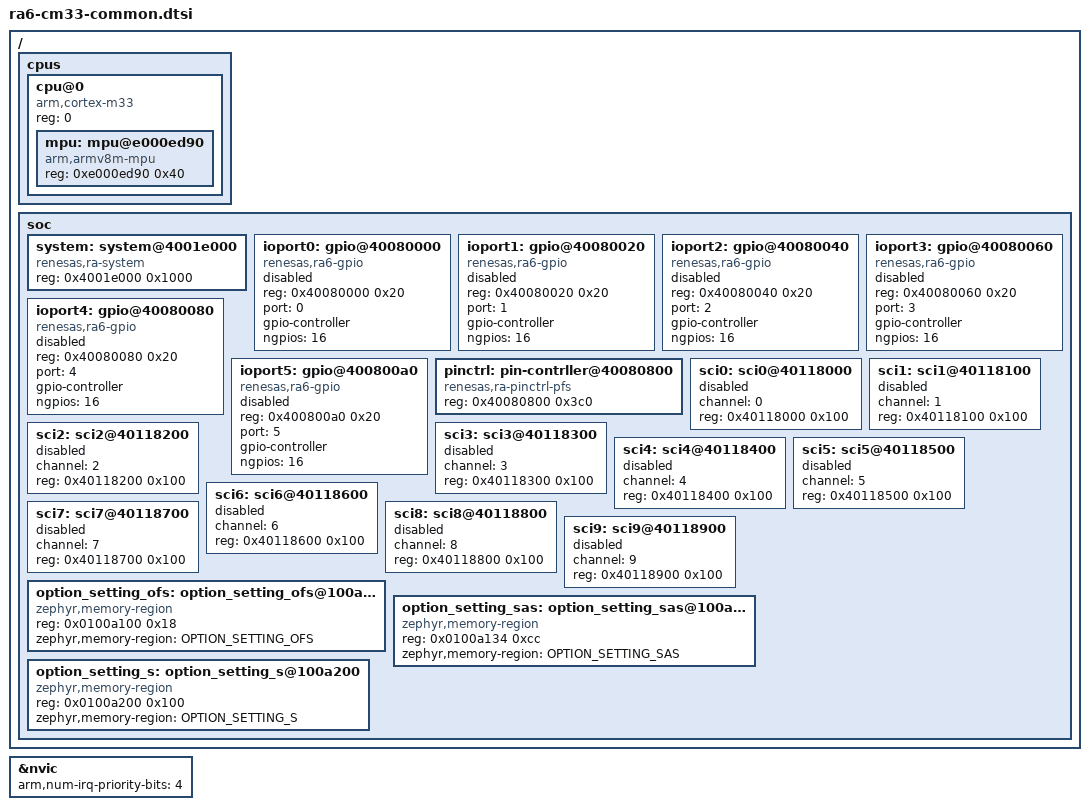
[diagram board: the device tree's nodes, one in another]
/*
 * Copyright (c) 2024 Renesas Electronics Corporation
 *
 * SPDX-License-Identifier: Apache-2.0
 */

#include <mem.h>
#include <arm/armv8-m.dtsi>
#include <zephyr/dt-bindings/pinctrl/renesas/pinctrl-ra.h>
#include <zephyr/dt-bindings/clock/ra_clock.h>
#include <freq.h>

/ {
	cpus {
		#address-cells = <1>;
		#size-cells = <0>;

		cpu@0 {
			device_type = "cpu";
			compatible = "arm,cortex-m33";
			reg = <0>;
			#address-cells = <1>;
			#size-cells = <1>;

			mpu: mpu@e000ed90 {
				compatible = "arm,armv8m-mpu";
				reg = <0xe000ed90 0x40>;
			};
		};
	};

	soc {
		system: system@4001e000 {
			compatible = "renesas,ra-system";
			reg = <0x4001e000 0x1000>;
			status = "okay";
		};

		ioport0: gpio@40080000 {
			compatible = "renesas,ra6-gpio";
			reg = <0x40080000 0x20>;
			port = <0>;
			gpio-controller;
			#gpio-cells = <2>;
			ngpios = <16>;
			status = "disabled";
		};

		ioport1: gpio@40080020 {
			compatible = "renesas,ra6-gpio";
			reg = <0x40080020 0x20>;
			port = <1>;
			gpio-controller;
			#gpio-cells = <2>;
			ngpios = <16>;
			status = "disabled";
		};

		ioport2: gpio@40080040 {
			compatible = "renesas,ra6-gpio";
			reg = <0x40080040 0x20>;
			port = <2>;
			gpio-controller;
			#gpio-cells = <2>;
			ngpios = <16>;
			status = "disabled";
		};

		ioport3: gpio@40080060 {
			compatible = "renesas,ra6-gpio";
			reg = <0x40080060 0x20>;
			port = <3>;
			gpio-controller;
			#gpio-cells = <2>;
			ngpios = <16>;
			status = "disabled";
		};

		ioport4: gpio@40080080 {
			compatible = "renesas,ra6-gpio";
			reg = <0x40080080 0x20>;
			port = <4>;
			gpio-controller;
			#gpio-cells = <2>;
			ngpios = <16>;
			status = "disabled";
		};

		ioport5: gpio@400800a0 {
			compatible = "renesas,ra6-gpio";
			reg = <0x400800a0 0x20>;
			port = <5>;
			gpio-controller;
			#gpio-cells = <2>;
			ngpios = <16>;
			status = "disabled";
		};

		pinctrl: pin-contrller@40080800 {
			compatible = "renesas,ra-pinctrl-pfs";
			reg = <0x40080800 0x3c0>;
			status = "okay";
		};

		sci0: sci0@40118000 {
			channel = <0>;
			reg = <0x40118000 0x100>;
			status = "disabled";
		};

		sci1: sci1@40118100 {
			channel = <1>;
			reg = <0x40118100 0x100>;
			status = "disabled";
		};

		sci2: sci2@40118200 {
			channel = <2>;
			reg = <0x40118200 0x100>;
			status = "disabled";
		};

		sci3: sci3@40118300 {
			channel = <3>;
			reg = <0x40118300 0x100>;
			status = "disabled";
		};

		sci4: sci4@40118400 {
			channel = <4>;
			reg = <0x40118400 0x100>;
			status = "disabled";
		};

		sci5: sci5@40118500 {
			channel = <5>;
			reg = <0x40118500 0x100>;
			status = "disabled";
		};

		sci6: sci6@40118600 {
			channel = <6>;
			reg = <0x40118600 0x100>;
			status = "disabled";
		};

		sci7: sci7@40118700 {
			channel = <7>;
			reg = <0x40118700 0x100>;
			status = "disabled";
		};

		sci8: sci8@40118800 {
			channel = <8>;
			reg = <0x40118800 0x100>;
			status = "disabled";
		};

		sci9: sci9@40118900 {
			channel = <9>;
			reg = <0x40118900 0x100>;
			status = "disabled";
		};

		option_setting_ofs: option_setting_ofs@100a100 {
			compatible = "zephyr,memory-region";
			reg = <0x0100a100 0x18>;
			zephyr,memory-region = "OPTION_SETTING_OFS";
			status = "okay";
		};

		option_setting_sas: option_setting_sas@100a134 {
			compatible = "zephyr,memory-region";
			reg = <0x0100a134 0xcc>;
			zephyr,memory-region = "OPTION_SETTING_SAS";
			status = "okay";
		};

		option_setting_s: option_setting_s@100a200 {
			compatible = "zephyr,memory-region";
			reg = <0x0100a200 0x100>;
			zephyr,memory-region = "OPTION_SETTING_S";
			status = "okay";
		};
	};
};

&nvic {
	arm,num-irq-priority-bits = <4>;
};
